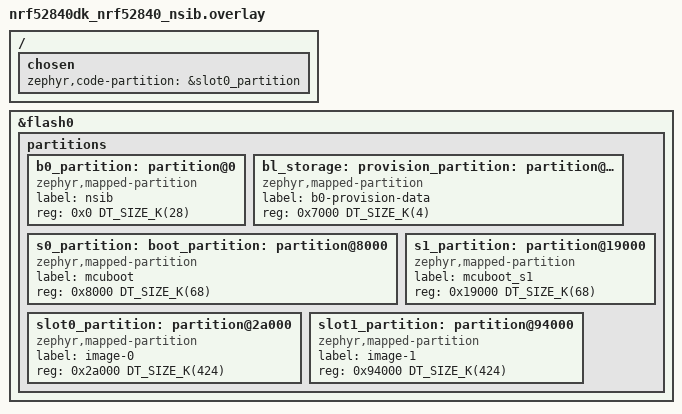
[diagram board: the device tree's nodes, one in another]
/*
 * Copyright (c) 2026 Nordic Semiconductor ASA
 *
 * SPDX-License-Identifier: LicenseRef-Nordic-5-Clause
 */

&flash0 {
	/delete-node/ partitions;

	partitions {
		ranges;
		#address-cells = <1>;
		#size-cells = <1>;

		b0_partition: partition@0 {
			compatible = "zephyr,mapped-partition";
			label = "nsib";
			reg = <0x0 DT_SIZE_K(28)>;
		};

		bl_storage: provision_partition: partition@7000 {
			compatible = "zephyr,mapped-partition";
			label = "b0-provision-data";
			reg = <0x7000 DT_SIZE_K(4)>;
		};

		s0_partition: boot_partition: partition@8000 {
			compatible = "zephyr,mapped-partition";
			label = "mcuboot";
			reg = <0x8000 DT_SIZE_K(68)>;
		};

		s1_partition: partition@19000 {
			compatible = "zephyr,mapped-partition";
			label = "mcuboot_s1";
			reg = <0x19000 DT_SIZE_K(68)>;
		};

		slot0_partition: partition@2a000 {
			compatible = "zephyr,mapped-partition";
			label = "image-0";
			reg = <0x2a000 DT_SIZE_K(424)>;
		};

		slot1_partition: partition@94000 {
			compatible = "zephyr,mapped-partition";
			label = "image-1";
			reg = <0x94000 DT_SIZE_K(424)>;
		};
	};
};

/ {
	chosen {
		zephyr,code-partition = &slot0_partition;
	};
};
